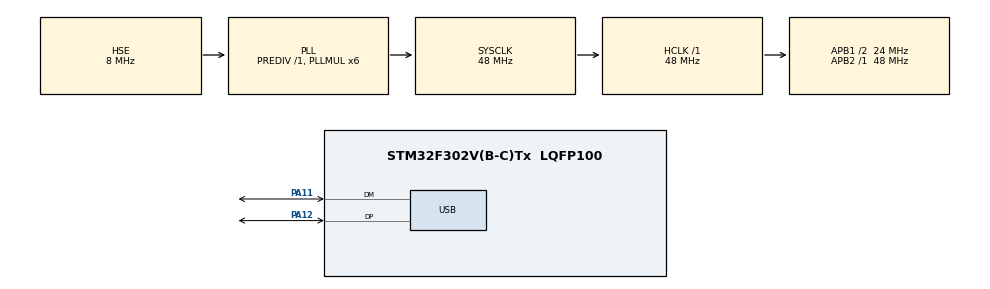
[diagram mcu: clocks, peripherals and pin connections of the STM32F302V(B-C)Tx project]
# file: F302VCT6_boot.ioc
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Mcu.Family=STM32F3
Mcu.Name=STM32F302V(B-C)Tx
Mcu.Package=LQFP100
NVIC.PriorityGroup=NVIC_PRIORITYGROUP_4
NVIC.USB_LP_CAN_RX0_IRQn=true\:0\:0\:false\:false\:true\:false\:true\:true
PA11.Mode=Device
PA11.Signal=USB_DM
PA12.Mode=Device
PA12.Signal=USB_DP
PA13.Mode=Serial_Wire
PA13.Signal=SYS_JTMS-SWDIO
PA14.Mode=Serial_Wire
PA14.Signal=SYS_JTCK-SWCLK
PC14-OSC32_IN.Mode=LSE-External-Oscillator
PC14-OSC32_IN.Signal=RCC_OSC32_IN
PC15-OSC32_OUT.Mode=LSE-External-Oscillator
PC15-OSC32_OUT.Signal=RCC_OSC32_OUT
PF0-OSC_IN.Mode=HSE-External-Oscillator
PF0-OSC_IN.Signal=RCC_OSC_IN
PF1-OSC_OUT.Mode=HSE-External-Oscillator
PF1-OSC_OUT.Signal=RCC_OSC_OUT
ProjectManager.HeapSize=0x200
ProjectManager.StackSize=0x400
ProjectManager.TargetToolchain=STM32CubeIDE
RCC.AHBFreq_Value=48000000
RCC.APB1CLKDivider=RCC_HCLK_DIV2
RCC.APB1Freq_Value=24000000
RCC.APB1TimFreq_Value=48000000
RCC.APB2Freq_Value=48000000
RCC.APB2TimFreq_Value=48000000
RCC.CortexFreq_Value=48000000
RCC.HCLKFreq_Value=48000000
RCC.HSE_VALUE=8000000
RCC.HSI_VALUE=8000000
RCC.PLLMUL=RCC_PLL_MUL6
RCC.SYSCLKFreq_VALUE=48000000
RCC.SYSCLKSourceVirtual=RCC_SYSCLKSOURCE_PLLCLK
RCC.USBFreq_Value=48000000
USB_DEVICE.CLASS_NAME_FS=CDC
USB_DEVICE.VirtualMode=Cdc
USB_DEVICE.VirtualModeFS=Cdc_FS
VP_USB_DEVICE_VS_USB_DEVICE_CDC_FS.Mode=CDC_FS
board=custom

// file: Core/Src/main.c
/* USER CODE BEGIN Header */
/**
  ******************************************************************************
  * @file           : main.c
  * @brief          : Main program body
  ******************************************************************************
  * @attention
  *
  * Copyright (c) 2024 STMicroelectronics.
  * All rights reserved.
  *
  * This software is licensed under terms that can be found in the LICENSE file
  * in the root directory of this software component.
  * If no LICENSE file comes with this software, it is provided AS-IS.
  *
  ******************************************************************************
  */
/* USER CODE END Header */
#include "main.h"

/* USER CODE BEGIN Includes */
#include "flash.h"
#include "bsl.h"
#include "stdio.h"
#include "bsl_packet.h"
/* USER CODE END Includes */

/* USER CODE BEGIN PM */
#define MAJOR 0
#define MINOR 1
/* USER CODE END PM */

/* USER CODE BEGIN PV */
const uint8_t BL_Version[2] = { MAJOR, MINOR };
/* USER CODE END PV */

void SystemClock_Config(void);
static void MX_GPIO_Init(void);

int main(void)
{

  /* MCU Configuration--------------------------------------------------------*/

  /* Reset of all peripherals, Initializes the Flash interface and the Systick. */
  HAL_Init();

  /* Configure the system clock */
  SystemClock_Config();

  /* Initialize all configured peripherals */
  MX_GPIO_Init();

  /* USER CODE BEGIN 2 */
  	bsl_init();

  	printf("starting boot loader (%d.%d)\r\n", BL_Version[0], BL_Version[1]);

  	uint64_t cfg_boot = 0;
  	bool     dfu_mode = false;

  	// Read configure boot
  	if (FLASH_OK != flash_read(CONFIG_START, (uint8_t *) &cfg_boot, 8))
  	{
  		printf("flash_read configure boot fail!\r\n");
  	}

  	switch (cfg_boot)
  	{
  	case BSL_BOOT_NORMAL:
  		printf("normal boot ...\r\n");
  		break;

  	case BSL_BOOT_FIRST_TIME:
  	case BSL_BOOT_DFU:
  		printf("first time boot / DFU boot ...\r\n");

  		// Set flag dfu_mode
  		dfu_mode = true;
  		break;

  	default:
  		printf("out of configure boot!\r\n");
  		break;
  	}

  	// None request boot
  	if (dfu_mode == false)
  	{
  		// Verify image
  		if (BSL_OK == bsl_verify_image())
  		{
  			printf("jump to application ...!\r\n");
  			flash_jump_to_app();
  		}
  		else
  		{
  			printf("verify image fail!\r\n");
  		}
  	}

  	printf("please update firmware!\r\n");
  /* USER CODE END 2 */

  /* Infinite loop */
  while (1)
  {
	  bsl_loop();
  }
}

void SystemClock_Config(void)
{
  RCC_OscInitTypeDef RCC_OscInitStruct = {0};
  RCC_ClkInitTypeDef RCC_ClkInitStruct = {0};
  RCC_PeriphCLKInitTypeDef PeriphClkInit = {0};

  /** Initializes the RCC Oscillators according to the specified parameters
  * in the RCC_OscInitTypeDef structure.
  */
  RCC_OscInitStruct.OscillatorType = RCC_OSCILLATORTYPE_HSE;
  RCC_OscInitStruct.HSEState = RCC_HSE_ON;
  RCC_OscInitStruct.HSEPredivValue = RCC_HSE_PREDIV_DIV1;
  RCC_OscInitStruct.HSIState = RCC_HSI_ON;
  RCC_OscInitStruct.PLL.PLLState = RCC_PLL_ON;
  RCC_OscInitStruct.PLL.PLLSource = RCC_PLLSOURCE_HSE;
  RCC_OscInitStruct.PLL.PLLMUL = RCC_PLL_MUL6;
  if (HAL_RCC_OscConfig(&RCC_OscInitStruct) != HAL_OK)
  {
    Error_Handler();
  }

  /** Initializes the CPU, AHB and APB buses clocks
  */
  RCC_ClkInitStruct.ClockType = RCC_CLOCKTYPE_HCLK|RCC_CLOCKTYPE_SYSCLK
                              |RCC_CLOCKTYPE_PCLK1|RCC_CLOCKTYPE_PCLK2;
  RCC_ClkInitStruct.SYSCLKSource = RCC_SYSCLKSOURCE_PLLCLK;
  RCC_ClkInitStruct.AHBCLKDivider = RCC_SYSCLK_DIV1;
  RCC_ClkInitStruct.APB1CLKDivider = RCC_HCLK_DIV2;
  RCC_ClkInitStruct.APB2CLKDivider = RCC_HCLK_DIV1;

  if (HAL_RCC_ClockConfig(&RCC_ClkInitStruct, FLASH_LATENCY_1) != HAL_OK)
  {
    Error_Handler();
  }
  PeriphClkInit.PeriphClockSelection = RCC_PERIPHCLK_USB;
  PeriphClkInit.USBClockSelection = RCC_USBCLKSOURCE_PLL;
  if (HAL_RCCEx_PeriphCLKConfig(&PeriphClkInit) != HAL_OK)
  {
    Error_Handler();
  }
}

static void MX_GPIO_Init(void)
{

  /* GPIO Ports Clock Enable */
  __HAL_RCC_GPIOC_CLK_ENABLE();
  __HAL_RCC_GPIOF_CLK_ENABLE();
  __HAL_RCC_GPIOA_CLK_ENABLE();

}

void Error_Handler(void)
{
  __disable_irq();
  while (1)
  {
  }
}
